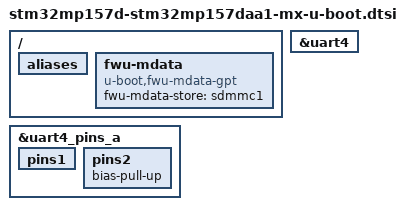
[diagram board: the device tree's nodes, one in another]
// SPDX-License-Identifier: (GPL-2.0-or-later OR BSD-3-Clause)
/*
 * Copyright (C) 2025, STMicroelectronics - All Rights Reserved
 * Author: STM32CubeMX code generation for STMicroelectronics.
 */

/* For more information on Device Tree configuration, please refer to
 * https://wiki.st.com/stm32mpu/wiki/Category:Device_tree_configuration
 */

/* USER CODE BEGIN includes */
#include "stm32mp15-scmi-u-boot.dtsi"
/* USER CODE END includes */

/ {

	/* USER CODE BEGIN root */
	aliases {
		//usb0 = &usbotg_hs;
	};

	fwu-mdata {
		compatible = "u-boot,fwu-mdata-gpt";
		fwu-mdata-store = <&sdmmc1>;
	};
	/* USER CODE END root */

}; /*root*/

/* USER CODE BEGIN addons */
&uart4 {
	bootph-all;
};

&uart4_pins_a {
	bootph-all;
	pins1 {
		bootph-all;
	};
	pins2 {
		bootph-all;
		/* pull-up on rx to avoid floating level */
		bias-pull-up;
	};
};
/* USER CODE END addons */

